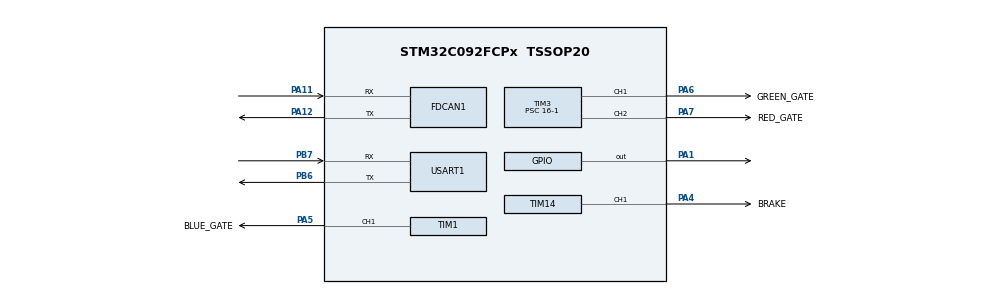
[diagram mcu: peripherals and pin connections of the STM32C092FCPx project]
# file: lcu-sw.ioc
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FDCAN1.CalculateBaudRateNominal=333333
FDCAN1.CalculateTimeBitNominal=3000
FDCAN1.CalculateTimeQuantumNominal=1000.0
Mcu.Family=STM32C0
Mcu.Name=STM32C092FCPx
Mcu.Package=TSSOP20
PA1.Signal=GPIO_Output
PA11\ [PA9].Mode=FDCAN_Activate
PA11\ [PA9].Signal=FDCAN1_RX
PA12\ [PA10].Mode=FDCAN_Activate
PA12\ [PA10].Signal=FDCAN1_TX
PA13.Mode=Serial_Wire
PA13.Signal=DEBUG_SWDIO
PA14-BOOT0.Mode=Serial_Wire
PA14-BOOT0.Signal=DEBUG_SWCLK
PA14-BOOT0__PA15.StandardMode=true
PA4.GPIO_Label=BRAKE
PA4.Signal=S_TIM14_CH1
PA5.GPIO_Label=BLUE_GATE
PA5.Signal=S_TIM1_CH1
PA6.GPIO_Label=GREEN_GATE
PA6.Signal=S_TIM3_CH1
PA7.GPIO_Label=RED_GATE
PA7.Signal=S_TIM3_CH2
PB0__PB1__PB2__PA8.StandardMode=true
PB3__PB4__PB5__PB6.StandardMode=true
PB6.Mode=Asynchronous
PB6.Signal=USART1_TX
PB7.Mode=Asynchronous
PB7.Signal=USART1_RX
PB7__PB8.StandardMode=true
PC14-OSCX_IN(PC14).Mode=HSE-External-Oscillator
PC14-OSCX_IN(PC14).Signal=RCC_OSCX_IN
PC15-OSCX_OUT(PC15).Mode=HSE-External-Oscillator
PC15-OSCX_OUT(PC15).Signal=RCC_OSCX_OUT
ProjectManager.HeapSize=0x200
ProjectManager.StackSize=0x400
ProjectManager.TargetToolchain=Makefile
RCC.ADCFreq_Value=16000000
RCC.AHBFreq_Value=16000000
RCC.CortexFreq_Value=16000000
RCC.EXTERNAL_CLOCK_VALUE=12288000
RCC.HCLKFreq_Value=16000000
RCC.HSE_VALUE=16000000
RCC.HSI_VALUE=48000000
RCC.LSE_VALUE=32768
RCC.SYSCLKFreq_VALUE=16000000
RCC.SYSCLKSource=RCC_SYSCLKSOURCE_HSE
SH.S_TIM14_CH1.0=TIM14_CH1,PWM Generation1 CH1
SH.S_TIM1_CH1.0=TIM1_CH1,PWM Generation1 CH1
SH.S_TIM3_CH1.0=TIM3_CH1,PWM Generation1 CH1
SH.S_TIM3_CH2.0=TIM3_CH2,PWM Generation2 CH2
TIM1.Channel-PWM\ Generation1\ CH1=TIM_CHANNEL_1
TIM1.Period=100-1
TIM1.Prescaler=16-1
TIM14.Channel=TIM_CHANNEL_1
TIM14.Period=100-1
TIM14.Prescaler=16-1
TIM3.Channel-PWM\ Generation1\ CH1=TIM_CHANNEL_1
TIM3.Channel-PWM\ Generation2\ CH2=TIM_CHANNEL_2
TIM3.Period=100-1
TIM3.Prescaler=16-1
USART1.VirtualMode-Asynchronous=VM_ASYNC
VP_TIM14_VS_ClockSourceINT.Mode=Enable_Timer
board=custom

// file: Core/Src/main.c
/* USER CODE BEGIN Header */
/**
  ******************************************************************************
  * @file           : main.c
  * @brief          : Main program body
  ******************************************************************************
  * @attention
  *
  * Copyright (c) 2026 STMicroelectronics.
  * All rights reserved.
  *
  * This software is licensed under terms that can be found in the LICENSE file
  * in the root directory of this software component.
  * If no LICENSE file comes with this software, it is provided AS-IS.
  *
  ******************************************************************************
  */
/* USER CODE END Header */
#include "main.h"
#include "fdcan.h"
#include "tim.h"
#include "usart.h"
#include "gpio.h"

/* USER CODE BEGIN Includes */
#include "fsm.h"
#include "eagletrt-api.h"
#include "brake-api.h"
#include "post.h"
/* USER CODE END Includes */

void SystemClock_Config(void);

int main(void) {

    /* MCU Configuration--------------------------------------------------------*/

    /* Reset of all peripherals, Initializes the Flash interface and the Systick. */
    HAL_Init();

    /* Configure the system clock */
    SystemClock_Config();

    /* Initialize all configured peripherals */
    MX_GPIO_Init();
    MX_FDCAN1_Init();
    MX_USART1_UART_Init();
    MX_TIM1_Init();
    MX_TIM3_Init();
    MX_TIM14_Init();
    /* USER CODE BEGIN 2 */
    //TODO: use future post module struct
    //temp!! i can cast function pointers to object pointers, this will be replaced by a post data structure in the future
    struct PostInitData init = { .brake_update_callback = tim_brake_update, .brake_start_callback = tim_brake_start };
    fsm_state_t current_state = fsm_run_state(FSM_STATE_INIT, (fsm_state_data_t *)&init);
    /* USER CODE END 2 */

    /* Infinite loop */
    /* USER CODE BEGIN WHILE */
    while (1) {
        current_state = fsm_run_state(current_state, NULL);
        /* USER CODE END WHILE */

    }
}

void SystemClock_Config(void) {
    RCC_OscInitTypeDef RCC_OscInitStruct = { 0 };
    RCC_ClkInitTypeDef RCC_ClkInitStruct = { 0 };

    __HAL_FLASH_SET_LATENCY(FLASH_LATENCY_0);

    /** Initializes the RCC Oscillators according to the specified parameters
  * in the RCC_OscInitTypeDef structure.
  */
    RCC_OscInitStruct.OscillatorType = RCC_OSCILLATORTYPE_HSE;
    RCC_OscInitStruct.HSEState = RCC_HSE_ON;
    if (HAL_RCC_OscConfig(&RCC_OscInitStruct) != HAL_OK) {
        Error_Handler();
    }

    /** Initializes the CPU, AHB and APB buses clocks
  */
    RCC_ClkInitStruct.ClockType = RCC_CLOCKTYPE_HCLK | RCC_CLOCKTYPE_SYSCLK | RCC_CLOCKTYPE_PCLK1;
    RCC_ClkInitStruct.SYSCLKSource = RCC_SYSCLKSOURCE_HSE;
    RCC_ClkInitStruct.SYSCLKDivider = RCC_SYSCLK_DIV1;
    RCC_ClkInitStruct.AHBCLKDivider = RCC_HCLK_DIV1;
    RCC_ClkInitStruct.APB1CLKDivider = RCC_APB1_DIV1;

    if (HAL_RCC_ClockConfig(&RCC_ClkInitStruct, FLASH_LATENCY_0) != HAL_OK) {
        Error_Handler();
    }
}

void Error_Handler(void) {
    __disable_irq();
    while (1) {
    }
}
